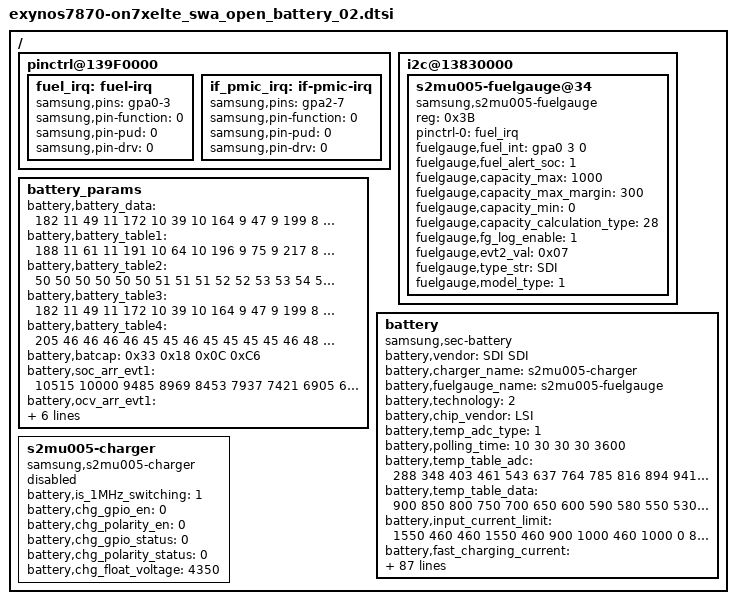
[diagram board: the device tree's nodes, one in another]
/*
 * SAMSUNG UNIVERSAL5433 board device tree source
 *
 * Copyright (c) 2013 Samsung Electronics Co., Ltd.
 *		http://www.samsung.com
 *
 * This program is free software; you can redistribute it and/or modify
 * it under the terms of the GNU General Public License version 2 as
 * published by the Free Software Foundation.
*/

/ {
	pinctrl@139F0000 {
		fuel_irq: fuel-irq {
			samsung,pins = "gpa0-3";
			samsung,pin-function = <0>;
			samsung,pin-pud = <0>;
			samsung,pin-drv = <0>;
		};
	};

	pinctrl@139F0000 {
		if_pmic_irq: if-pmic-irq {
			samsung,pins = "gpa2-7";
			samsung,pin-function = <0>;
			samsung,pin-pud = <0>;
			samsung,pin-drv = <0>;
		};
	};

	i2c@13830000 {
		status = "okay";
		s2mu005-fuelgauge@34 {
			compatible = "samsung,s2mu005-fuelgauge";
			reg = <0x3B>;
			pinctrl-names = "default";
			pinctrl-0 = <&fuel_irq>;
			fuelgauge,fuel_int = <&gpa0 3 0>;
			fuelgauge,fuel_alert_soc = <1>;
			fuelgauge,capacity_max = <1000>;
			fuelgauge,capacity_max_margin = <300>;
			fuelgauge,capacity_min = <0>;
			fuelgauge,capacity_calculation_type = <28>;
			fuelgauge,fg_log_enable = <1>;
			fuelgauge,evt2_val = <0x07>;
			fuelgauge,type_str = "SDI";
			fuelgauge,model_type = <1>;
		};
	};

	battery_params {
			battery,battery_data =
			<
				/***** battery data for 4.35 *****/
				/* battery,battery_table3 */
				182 11 49 11 172 10 39 10 164 9
				47 9 199 8 95 8 228 7 162 7
				71 7 232 6 169 6 125 6 91 6
				64 6 39 6 1 6 201 5 141 5
				101 5 169 1 219 8 108 8 254 7
				143 7 33 7 178 6 68 6 213 5
				103 5 248 4 138 4 27 4 173 3
				63 3 208 2 98 2 243 1 133 1
				22 1 168 0 57 0 203 15

				/* battery,battery_table4 */
				205 46 46 46 46 45 45 46 45 45
				45 45 46 48 49 51 53 55 60 71
				83 154

				/* battery,batcap */
				0x33 0x18 0x0C 0xC6 /* [0x0F] [0x0E] [0x11] [0x10] */
				/* battery,accum */
				0xE1 0x07 /* [0x44] [0x45] */

				/* battery,soc_arr_val */
				11068 10529 9990 9450 8911 8371 7832 7292 6753 6213 5674 5134 4595 4056 3516 2977 2437 1898 1358 819 279 (-260)
				/* battery,ocv_arr_val */
				44640 43990 43339 42691 42051 41482 40971 40466 39864 39543 39096 38632 38324 38110 37945 37815 37693 37505 37232 36937 36741 32075

				/***** battery data for 4.33 *****/
				/* battery,battery_table3 */
				95 11 220 10 89 10 215 9 100 9
				248 8 145 8 29 8 193 7 134 7
				46 7 210 6 158 6 119 6 88 6
				62 6 30 6 246 5 192 5 144 5
				3 5 135 1 167 8 59 8 208 7
				100 7 249 6 141 6 34 6 182 5
				75 5 223 4 116 4 8 4 157 3
				49 3 198 2 90 2 239 1 131 1
				24 1 172 0 65 0 213 15

				/* battery,battery_table4 */
				49 49 49 49 49 49 49 49 49 48
				48 48 49 49 50 52 53 55 57 59
				68 145

				/* battery,batcap */
				0x32 0xB4 0x0C 0xAD /* [0x0F] [0x0E] [0x11] [0x10] */
				/* battery,accum */
				0xc3 0x7 /* [0x44] [0x45] */

				/* battery,soc_arr_val */
				10814 10290 9765 9240 8715 8189 7665 7140 6615 6090 5565 5040 4516 3991 3466 2940 2416 1891 1366 840 316 (-208)
				/* battery,ocv_arr_val */
				44212 43573 42934 42300 41739 41209 40706 40144 39691 39403 38974 38527 38270 38080 37929 37803 37647 37453 37188 36955 36263 31907

				/***** battery data for 4.31 *****/
				/* battery,battery_table3 */
				45 11 175 10 50 10 181 9 70 9
				221 8 127 8 253 7 186 7 117 7
				26 7 200 6 151 6 114 6 85 6
				59 6 27 6 244 5 190 5 144 5
				2 5 112 1 173 8 65 8 213 7
				105 7 254 6 146 6 38 6 186 5
				78 5 226 4 118 4 10 4 159 3
				51 3 199 2 91 2 239 1 131 1
				24 1 172 0 64 0 212 15

				/* battery,battery_table4 */
				48 48 49 49 49 49 48 48 48 48
				47 48 48 49 50 51 52 54 57 60
				69 156

				/* battery,batcap */
				0x31 0xEC 0x0C 0x7B /* [0x0F] [0x0E] [0x11] [0x10] */
				/* battery,accum */
				0xc3 0x7 /* [0x44] [0x45] */

				/* battery,soc_arr_val */
				10845 10318 9791 9265 8738 8211 7685 7158 6631 6105 5578 5051 4525 3998 3472 2945 2418 1892 1365 838 312 (-214)
				/* battery,ocv_arr_val */
				43970 43356 42742 42133 41590 41080 40621 39987 39657 39323 38878 38476 38238 38058 37914 37790 37633 37440 37176 36952 36259 31798

				/***** battery data for 4.29 *****/
				/* battery,battery_table3 */
				254 10 133 10 12 10 147 9 39 9
				194 8 109 8 229 7 176 7 100 7
				8 7 190 6 145 6 110 6 81 6
				57 6 26 6 243 5 189 5 144 5
				9 5 160 1 172 8 64 8 213 7
				105 7 253 6 145 6 37 6 186 5
				78 5 226 4 118 4 10 4 159 3
				51 3 199 2 91 2 240 1 132 1
				24 1 172 0 64 0 213 15

				/* battery,battery_table4 */
				101 101 100 99 100 100 99 99 99 98
				99 99 99 100 102 104 106 109 113 120
				132 178

				/* battery,batcap */
				0x31 0x24 0x0C 0x49 /* [0x0F] [0x0E] [0x11] [0x10] */
				/* battery,accum */
				0xc3 0x7 /* [0x44] [0x45] */

				/* battery,soc_arr_val */
				10841 10315 9789 9262 8736 8210 7683 7157 6631 6104 5578 5051 4525 3999 3472 2945 2420 1893 1366 840 314 (-212)
				/* battery,ocv_arr_val */
				43742 43150 42558 41968 41441 40949 40533 39869 39610 39239 38787 38429 38207 38035 37898 37779 37627 37436 37172 36953 36293 32032

				/***** battery data for 4.24 *****/
				/* battery,battery_table3 */
				135 10 24 10 169 9 58 9 215 8
				133 8 1 8 191 7 135 7 54 7
				220 6 167 6 129 6 99 6 74 6
				49 6 17 6 233 5 178 5 138 5
				243 4 135 1 170 8 63 8 211 7
				103 7 251 6 144 6 36 6 184 5
				77 5 225 4 117 4 9 4 158 3
				50 3 198 2 91 2 239 1 131 1
				24 1 172 0 64 0 212 15

				/* battery,battery_table4 */
				95 95 95 95 95 95 95 95 94 94
				95 95 96 97 98 99 102 105 108 115
				129 180

				/* battery,batcap */
				0x2E 0xE0 0x0B 0xB8 /* [0x0F] [0x0E] [0x11] [0x10] */
				/* battery,accum */
				0xE0 0x7 /* [0x44] [0x45] */

				/* battery,soc_arr_val */
				10832 10306 9780 9254 8728 8202 7675 7150 6624 6098 5572 5046 4521 3995 3469 2943 2417 1891 1365 839 313 (-213)
				/* battery,ocv_arr_val */
				43157 42615 42073 41532 41051 40648 40007 39682 39407 39014 38572 38318 38130 37982 37861 37740 37581 37386 37121 36925 36189 31910
			>;
			battery,battery_table1 = <188 11 61 11 191 10 64 10 196 9
					75 9 217 8 110 8 13 8 173 7
					66 7 235 6 177 6 132 6 96 6
					67 6 31 6 242 5 164 5 124 5
					23 5 144 1 216 8 105 8 251 7
					141 7 30 7 176 6 65 6 211 5
					101 5 246 4 136 4 25 4 171 3
					60 3 206 2 95 2 241 1 131 1
					20 1 166 0 55 0 201 15>;

			battery,battery_table2 = <50 50 50 50 50 50 51 51 51 52
					52 53 53 54 54 55 55 56 57 59
					63 154>;

			battery,battery_table3 = <182 11 49 11 172 10 39 10 164 9
					47 9 199 8 95 8 228 7 162 7
					71 7 232 6 169 6 125 6 91 6
					64 6 39 6 1 6 201 5 141 5
					101 5 169 1 219 8 108 8 254 7
					143 7 33 7 178 6 68 6 213 5
					103 5 248 4 138 4 27 4 173 3
					63 3 208 2 98 2 243 1 133 1
					22 1 168 0 57 0 203 15>;

			battery,battery_table4 = <205 46 46 46 46 45 45 46 45 45
					45 45 46 48 49 51 53 55 60 71
					83 154>;

			battery,batcap = <0x33 0x18 0x0C 0xC6>; /* [0x0F] [0x0E] [0x11] [0x10] */

			battery,soc_arr_evt1 = <10515 10000 9485 8969 8453 7937 7421 6905 6389 5873 5358 4842 4326 3810 3294 2778 2263 1747 1231 716 200 (-269)>;
			battery,ocv_arr_evt1 = <44051 43459 42867 42288 41716 41175 40664 40199 39779 39268 38784 38482 38250 38059 37906 37778 37594 37368 36957 36835 36289 31955>;

			battery,soc_arr_evt2 = <11068 10529 9990 9450 8911 8371 7832 7292 6753 6213 5674 5134 4595 4056 3516 2977 2437 1898 1358 819 279 (-260)>;
			battery,ocv_arr_evt2 = <44640 43990 43339 42691 42051 41482 40971 40466 39864 39543 39096 38632 38324 38110 37945 37815 37693 37505 37232 36937 36741 32075>;
			
			battery,FG_Accumulative_rate_evt2 =<0xE1 0x07>;
	};

	battery {
		status = "okay";

		pinctrl-names = "default";

		compatible = "samsung,sec-battery";
		battery,vendor = "SDI SDI";
		battery,charger_name = "s2mu005-charger";
		battery,fuelgauge_name = "s2mu005-fuelgauge";
		battery,technology = <2>; /* POWER_SUPPLY_TECHNOLOGY_LION */

		battery,chip_vendor = "LSI";
		battery,temp_adc_type = <1>; /* SEC_BATTERY_ADC_TYPE_AP */

		battery,polling_time = <10 30 30 30 3600>;

		battery,temp_table_adc = <288 348 403 461 543 637 764 785 816 894 941 966 1025 1088 1121 1188 1369 1572
								1745 1967 2192 2427 2656 2873 2957 3001 3076 3147 3179 3238 3295 3392 3506 3571>;

		battery,temp_table_data = <900 850 800 750 700 650 600 590 580 550 530 520 500 480 470 450 400 350 
								300 250 200 150 100 50 30 20 0 (-20) (-30) (-50) (-70) (-100) (-150) (-200)>;

		battery,input_current_limit = <1550 460 460 1550 460 900 1000 460 1000 0 820 820 820 1900 1550 0 0 400 700 1300 300 1000 1550 0 1667 1667 1000 1667 80 1800 1667 1400 1000 1000 820 820>;
		battery,fast_charging_current = <1800 0 0 1800 460 1200 1000 460 1200 0 1200 1200 1200 1700 2100 0 0 400 700 1300 300 1000 1500 0 2550 2550 1000 2550 80 1800 1000 1400 0 1000 1200 1200>;
		battery,full_check_current_1st = <325 0 0 325 325 325 325 325 325 0 325 325 325 325 325 0 0 325 325 325 325 325 325 0 325 325 325 325 0 325 325 325 0 325 325 325>;
		battery,full_check_current_2nd = <175 0 0 175 175 175 175 175 175 0 175 175 175 175 175 0 0 175 175 175 175 175 175 0 175 175 175 175 0 175 175 175 0 175 175 175>;

		battery,wireless_cc_cv = <86>;
		battery,inbat_voltage = <1>;

		battery,inbat_voltage_table_adc = <2847 2829 2802 2770 2743 2715 2688 2664 2634 2603 
						2573 2544 2515 2485 2456 2431 2406 2377 2347 2317 2289 448>;
		battery,inbat_voltage_table_data = <4380 4350 4300 4250 4200 4150 4100 4050 4000 3950
						3900 3850 3800 3750 3700 3650 3600 3550 3500 3450 3400 1>;

		battery,adc_check_count = <5>;

		battery,cable_check_type = <4>; /* SEC_BATTERY_CABLE_CHECK_PSY */
		battery,cable_source_type = <1>; /* SEC_BATTERY_CABLE_SOURCE_EXTERNAL */
		battery,polling_type = <1>; /* SEC_BATTERY_MONITOR_ALARM */
		battery,monitor_initial_count = <0>;

		battery,battery_check_type = <5>; /* SEC_BATTERY_CHECK_CHARGER */
		battery,check_count = <0>;

		battery,ovp_uvlo_check_type = <3>; /* SEC_BATTERY_OVP_UVLO_CHGPOLLING */

		battery,check_adc_max = <1440>;
		battery,check_adc_min = <0>;

		battery,thermal_source = <2>; /* SEC_BATTERY_THERMAL_SOURCE_ADC */

		battery,temp_check_type = <2>; /* SEC_BATTERY_TEMP_CHECK_TEMP */
		battery,temp_check_count = <1>;
		battery,temp_highlimit_threshold_normal = <800>;
		battery,temp_highlimit_recovery_normal = <750>;
		battery,temp_high_threshold_normal = <500>;
		battery,temp_high_recovery_normal = <450>;
		battery,temp_low_threshold_normal = <0>;
		battery,temp_low_recovery_normal = <50>;
		battery,temp_highlimit_threshold_lpm = <800>;
		battery,temp_highlimit_recovery_lpm = <750>;
		battery,temp_high_threshold_lpm = <500>;
		battery,temp_high_recovery_lpm = <450>;
		battery,temp_low_threshold_lpm = <0>;
		battery,temp_low_recovery_lpm = <50>;

		battery,full_check_type = <2>; /* SEC_BATTERY_FULLCHARGED_FG_CURRENT */
		battery,full_check_type_2nd = <2>; /* SEC_BATTERY_FULLCHARGED_FG_CURRENT */
		battery,full_check_count = <2>;
		battery,chg_gpio_full_check = <0>;
		battery,chg_polarity_full_check = <1>;

		/* SEC_BATTERY_FULL_CONDITION_SOC |
		   SEC_BATTERY_FULL_CONDITION_NOTIMEFULL |
		   SEC_BATTERY_FULL_CONDITION_VCELL */
		battery,full_condition_type = <15>;
		battery,full_condition_soc = <93>;
		battery,full_condition_vcell = <4290>;

		battery,recharge_check_count = <2>;
		battery,recharge_condition_type = <4>; /* SEC_BATTERY_RECHARGE_CONDITION_VCELL */
		battery,recharge_condition_soc = <98>;
		battery,recharge_condition_vcell = <4250>;
		
		battery,expired_time = <14400>;
		battery,recharging_expired_time = <5400>;
		battery,standard_curr = <1602>;

		battery,charging_total_time = <21600>;
		battery,recharging_total_time = <5400>;
		battery,charging_reset_time = <0>;

		battery,chg_float_voltage = <4350>;

		battery,self_discharging_en;
		battery,force_discharging_limit = <650>;
		battery,force_discharging_recov = <550>;
		battery,self_discharging_voltage_limit = <4250>;
		battery,discharging_adc_max = <2600>;
		battery,discharging_adc_min = <1700>;
		battery,discharging_ntc_limit = <2750>;

		battery,self_discharging_temp_block = <600>;
		battery,self_discharging_volt_block = <4250>;
		battery,self_discharging_temp_recov = <550>;
		battery,self_discharging_temp_pollingtime = <400>;

		battery,swelling_high_temp_block = <410>;
		battery,swelling_high_temp_recov = <390>;
		
		battery,swelling_low_temp_2step_mode = <1>;
		battery,swelling_low_temp_block_1st = <150>;
		battery,swelling_low_temp_recov_1st = <200>;
		battery,swelling_low_temp_block_2nd = <50>;
		battery,swelling_low_temp_recov_2nd = <100>;
		
		battery,swelling_low_temp_current = <950>;	/* 0.5C */
		battery,swelling_low_temp_topoff = <175>;	/* 0.05C */
		battery,swelling_high_temp_current = <1450>;	/* 0.7C */
		battery,swelling_high_temp_topoff = <175>;	/* 0.05C */
		
		battery,swelling_drop_float_voltage = <4150>;
		battery,swelling_offset_voltage = <20>;
		battery,swelling_high_rechg_voltage = <4000>;
		battery,swelling_low_rechg_voltage = <4000>;

		battery,siop_input_limit_current = <1550>;
		battery,siop_charging_limit_current = <1000>;

		/* cycle, chg_float_voltage, recharge_condition_vcell, full_condition_vcell, full_condition_soc */
		battery,age_data = <0 4350 4250 4250 92	/*4.35*/
				200 4330 4230 4230 91	/*4.33*/
				250 4310 4210 4210 89	/*4.31*/
				300 4290 4190 4190 87	/*4.29*/
				1000 4240 4140 4140 83	/*4.24*/
				>;

		io-channels = <&exynos_adc 1>,<&exynos_adc 3>;
		io-channel-names = "adc-temp","adc-in-bat";
		#io-channel-cells = <1>;
		io-channel-ranges;
	};

	s2mu005-charger {
		status = "disable";
		compatible = "samsung,s2mu005-charger";
		battery,is_1MHz_switching = <1>;
		battery,chg_gpio_en = <0>;
		battery,chg_polarity_en = <0>;
		battery,chg_gpio_status = <0>;
		battery,chg_polarity_status = <0>;
		battery,chg_float_voltage = <4350>;
	};
};
